# PIC32MZ1025W104132 device description
Architecture: MIPS; Family: PIC32MZW; Series: PIC32MZW
Registers are 32-bit, read-write, no defined reset value unless marked. A register's access mark holds for its fields unless they carry their own. Offsets are from the block's base; [hi:lo] are bit positions; lines under a group give offsets from that group; {n}, {i} and the like mark numbered series; 'fields as' and 'values as' point back to an identical list.

## INT
Instances: INT 0x1f810000 in periph_pb1b
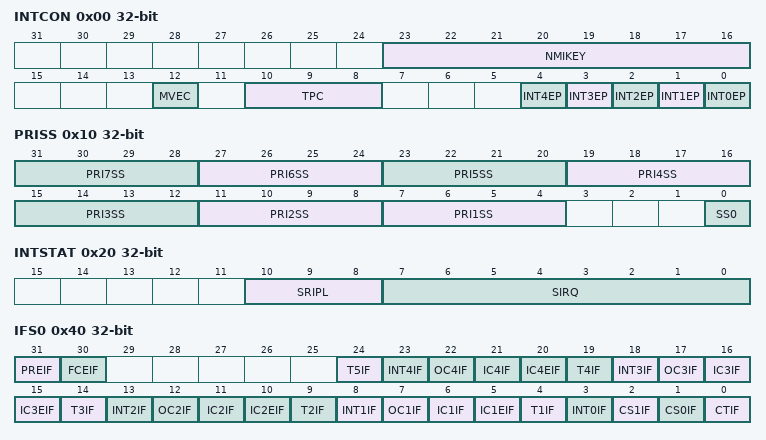
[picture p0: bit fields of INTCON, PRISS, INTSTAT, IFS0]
0x00 INTCON — Interrupt Control Register
  [23:16] NMIKEY
  [12] MVEC — Multi Vector Configuration bit
    1=Interrupt controller configured for multi vectored mode; 0=Interrupt controller configured for single vectored mode
  [10:8] TPC — Interrupt Proximity Timer Control bits
    {v}=Interrupts of group priority {v} or lower start the Interrupt Proximity timer (v=2..7); 1=Interrupts of group priority 1 start the Interrupt Proximity timer; 0=Disables Interrupt Proximity timer
  [n] INT{n}EP (n=0..4) — External Interrupt {n} Edge
    1=Rising edge; 0=Falling edge
0x10 PRISS — Priority Shadow Select Register
  [4n+3:4n] PRI{n}SS (n=2..7) — Interrupt with Priority Level {n} Shadow Set bits
    {v}=Interrupt with a priority level of {n} uses Shadow Set {v} (v=0..7)
  [7:4] PRI1SS — Interrupt with Priority Level 1 Shadow Set bits
    7=Interrupt with a priority level of 1 uses Shadow Set 7; {v}=Interrupt with a priority level of 1 uses Shadow Set {v} (v=0..5)
  [0] SS0 — Single Vector Shadow Register Set bit
    1=Single vector is presented with a shadow set; 0=Single vector is not presented with a shadow set
0x20 INTSTAT ro — Interrupt Status Register
  [10:8] SRIPL — Requested Priority Level bits for Single Vector Mode bits
    0=The priority level of the latest interrupt presented to the CPU is 0; 0=The priority level of the latest interrupt presented to the CPU is 1; 0=The priority level of the latest interrupt presented to the CPU is 2; 0=The priority level of the latest interrupt presented to the CPU is 3; 0=The priority level of the latest interrupt presented to the CPU is 4; 0=The priority level of the latest interrupt presented to the CPU is 5; 0=The priority level of the latest interrupt presented to the CPU is 6; 0=The priority level of the latest interrupt presented to the CPU is 7
  [7:0] SIRQ — Last Interrupt Request Serviced Status bits
    255=The last interrupt request number serviced by the CPU was 255; 254=The last interrupt request number serviced by the CPU was 254; 2=The last interrupt request number serviced by the CPU was 2; 1=The last interrupt request number serviced by the CPU was 1; 0=The last interrupt request number serviced by the CPU was 0
0x30 IPTMR — Interrupt Proximity Timer Register
  [31:0] IPTMR — Interrupt Proximity Timer Reload bits
    0=reload value of 0; 1=reload value of 1; 0xffffffff=reload value of 2^32-1
0x40 IFS0 — Interrupt Flag Status Register 0
  [all] fields
    1=Interrupt request has occurred; 0=No interrupt request has occurred
  [31] PREIF — Interrupt Flag Status bit 31
  [30] FCEIF — Interrupt Flag Status bit 30
  [5n-1] T{n}IF (n=1..5) — Interrupt Flag Status bit {5n-1}
  [5n+3] INT{n}IF (n=0..4) — Interrupt Flag Status bit {5n+3}
  [5n+2] OC{n}IF (n=1..4) — Interrupt Flag Status bit {5n+2}
  [5n+1] IC{n}IF (n=1..4) — Interrupt Flag Status bit {5n+1}
  [5n] IC{n}EIF (n=1..4) — Interrupt Flag Status bit {5n}
  [2] CS1IF — Interrupt Flag Status bit 2
  [1] CS0IF — Interrupt Flag Status bit 1
  [0] CTIF — Interrupt Flag Status bit 0
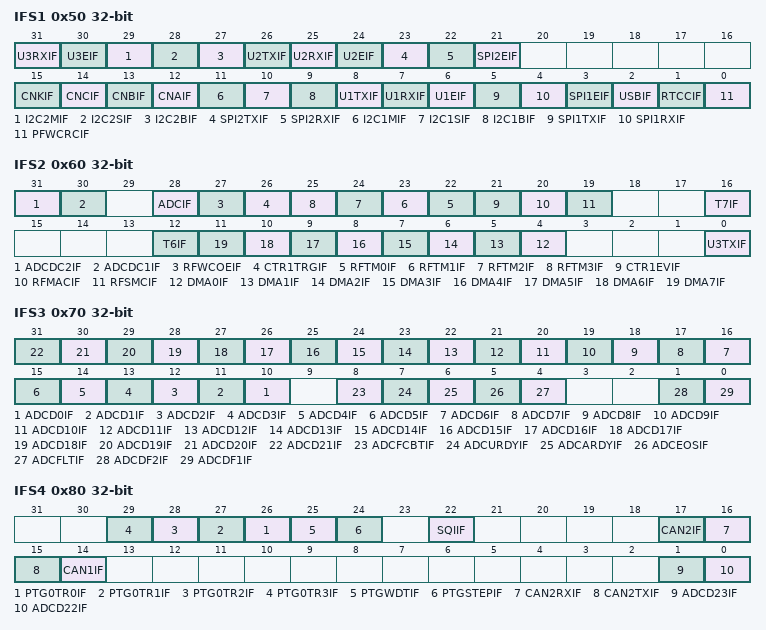
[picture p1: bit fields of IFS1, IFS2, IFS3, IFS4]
0x50 IFS1 — Interrupt Flag Status Register 1
  [all] fields
    values as the fields of IFS0
  [31] U3RXIF — Interrupt Flag Status bit 31
  [30] U3EIF — Interrupt Flag Status bit 30
  [29] I2C2MIF — Interrupt Flag Status bit 29
  [28] I2C2SIF — Interrupt Flag Status bit 28
  [27] I2C2BIF — Interrupt Flag Status bit 27
  [26] U2TXIF — Interrupt Flag Status bit 26
  [25] U2RXIF — Interrupt Flag Status bit 25
  [24] U2EIF — Interrupt Flag Status bit 24
  [23] SPI2TXIF — Interrupt Flag Status bit 23
  [22] SPI2RXIF — Interrupt Flag Status bit 22
  [21] SPI2EIF — Interrupt Flag Status bit 21
  [15] CNKIF — Interrupt Flag Status bit 15
  [14] CNCIF — Interrupt Flag Status bit 14
  [13] CNBIF — Interrupt Flag Status bit 13
  [12] CNAIF — Interrupt Flag Status bit 12
  [11] I2C1MIF — Interrupt Flag Status bit 11
  [10] I2C1SIF — Interrupt Flag Status bit 10
  [9] I2C1BIF — Interrupt Flag Status bit 9
  [8] U1TXIF — Interrupt Flag Status bit 8
  [7] U1RXIF — Interrupt Flag Status bit 7
  [6] U1EIF — Interrupt Flag Status bit 6
  [5] SPI1TXIF — Interrupt Flag Status bit 5
  [4] SPI1RXIF — Interrupt Flag Status bit 4
  [3] SPI1EIF — Interrupt Flag Status bit 3
  [2] USBIF — Interrupt Flag Status bit 2
  [1] RTCCIF — Interrupt Flag Status bit 1
  [0] PFWCRCIF — Interrupt Flag Status bit 0
0x60 IFS2 — Interrupt Flag Status Register 2
  [all] fields
    values as the fields of IFS0
  [31] ADCDC2IF — Interrupt Flag Status bit 31
  [30] ADCDC1IF — Interrupt Flag Status bit 30
  [28] ADCIF — Interrupt Flag Status bit 28
  [27] RFWCOEIF — Interrupt Flag Status bit 27
  [26] CTR1TRGIF — Interrupt Flag Status bit 26
  [n+22] RFTM{n}IF (n=0..3) — Interrupt Flag Status bit {n+22}
  [21] CTR1EVIF — Interrupt Flag Status bit 21
  [20] RFMACIF — Interrupt Flag Status bit 20
  [19] RFSMCIF — Interrupt Flag Status bit 19
  [16] T7IF — Interrupt Flag Status bit 16
  [12] T6IF — Interrupt Flag Status bit 12
  [n+4] DMA{n}IF (n=0..7) — Interrupt Flag Status bit {n+4}
  [0] U3TXIF — Interrupt Flag Status bit 0
0x70 IFS3 — Interrupt Flag Status Register 3
  [all] fields
    values as the fields of IFS0
  [n+10] ADCD{n}IF (n=0..21) — Interrupt Flag Status bit {n+10}
  [8] ADCFCBTIF — Interrupt Flag Status bit 8
  [7] ADCURDYIF — Interrupt Flag Status bit 7
  [6] ADCARDYIF — Interrupt Flag Status bit 6
  [5] ADCEOSIF — Interrupt Flag Status bit 5
  [4] ADCFLTIF — Interrupt Flag Status bit 4
  [1] ADCDF2IF — Interrupt Flag Status bit 1
  [0] ADCDF1IF — Interrupt Flag Status bit 0
0x80 IFS4 — Interrupt Flag Status Register 4
  [all] fields
    values as the fields of IFS0
  [n+26] PTG0TR{n}IF (n=0..3) — Interrupt Flag Status bit {n+26}
  [25] PTGWDTIF — Interrupt Flag Status bit 25
  [24] PTGSTEPIF — Interrupt Flag Status bit 24
  [22] SQIIF — Interrupt Flag Status bit 22
  [17] CAN2IF — Interrupt Flag Status bit 17
  [16] CAN2RXIF — Interrupt Flag Status bit 16
  [15] CAN2TXIF — Interrupt Flag Status bit 15
  [14] CAN1IF — Interrupt Flag Status bit 14
  [1] ADCD23IF — Interrupt Flag Status bit 1
  [0] ADCD22IF — Interrupt Flag Status bit 0
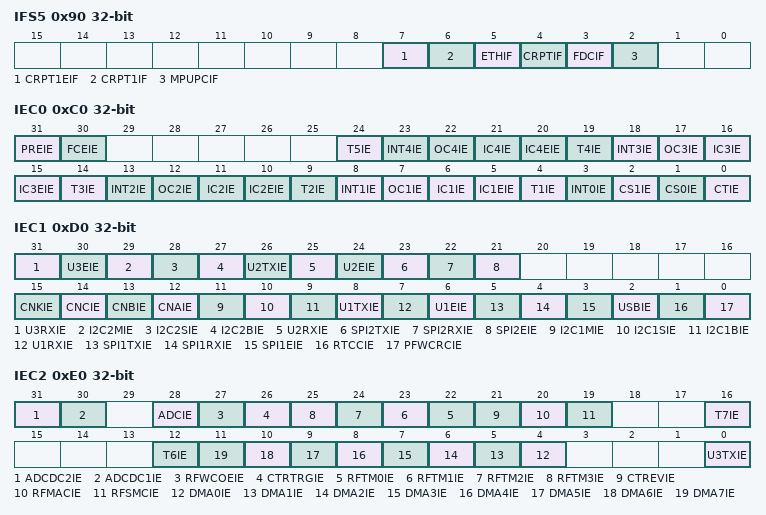
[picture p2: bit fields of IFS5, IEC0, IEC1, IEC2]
0x90 IFS5 — Interrupt Flag Status Register 5
  [all] fields
    values as the fields of IFS0
  [7] CRPT1EIF — Interrupt Flag Status bit 7
  [6] CRPT1IF — Interrupt Flag Status bit 6
  [5] ETHIF — Interrupt Flag Status bit 5
  [4] CRPTIF — Interrupt Flag Status bit 4
  [3] FDCIF — Interrupt Flag Status bit 3
  [2] MPUPCIF — Interrupt Flag Status bit 2
0xC0 IEC0 — Interrupt Enable Control Register 0
  [all] fields
    1=Interrupt is enabled; 0=Interrupt is disabled
  [31] PREIE — Interrupt Enable bit 31
  [30] FCEIE — Interrupt Enable bit 30
  [5n-1] T{n}IE (n=1..5) — Interrupt Enable bit {5n-1}
  [5n+3] INT{n}IE (n=0..4) — Interrupt Enable bit {5n+3}
  [5n+2] OC{n}IE (n=1..4) — Interrupt Enable bit {5n+2}
  [5n+1] IC{n}IE (n=1..4) — Interrupt Enable bit {5n+1}
  [5n] IC{n}EIE (n=1..4) — Interrupt Enable bit {5n}
  [2] CS1IE — Interrupt Enable bit 2
  [1] CS0IE — Interrupt Enable bit 1
  [0] CTIE — Interrupt Enable bit 0
0xD0 IEC1 — Interrupt Enable Control Register 1
  [all] fields
    1=Interrupt is enabled; 0=Interrupt is disabled
  [31] U3RXIE — Interrupt Enable bit 31
  [30] U3EIE — Interrupt Enable bit 30
  [29] I2C2MIE — Interrupt Enable bit 29
  [28] I2C2SIE — Interrupt Enable bit 28
  [27] I2C2BIE — Interrupt Enable bit 27
  [26] U2TXIE — Interrupt Enable bit 26
  [25] U2RXIE — Interrupt Enable bit 25
  [24] U2EIE — Interrupt Enable bit 24
  [23] SPI2TXIE — Interrupt Enable bit 23
  [22] SPI2RXIE — Interrupt Enable bit 22
  [21] SPI2EIE — Interrupt Enable bit 21
  [15] CNKIE — Interrupt Enable bit 15
  [14] CNCIE — Interrupt Enable bit 14
  [13] CNBIE — Interrupt Enable bit 13
  [12] CNAIE — Interrupt Enable bit 12
  [11] I2C1MIE — Interrupt Enable bit 11
  [10] I2C1SIE — Interrupt Enable bit 10
  [9] I2C1BIE — Interrupt Enable bit 9
  [8] U1TXIE — Interrupt Enable bit 8
  [7] U1RXIE — Interrupt Enable bit 7
  [6] U1EIE — Interrupt Enable bit 6
  [5] SPI1TXIE — Interrupt Enable bit 5
  [4] SPI1RXIE — Interrupt Enable bit 4
  [3] SPI1EIE — Interrupt Enable bit 3
  [2] USBIE — Interrupt Enable bit 2
  [1] RTCCIE — Interrupt Enable bit 1
  [0] PFWCRCIE — Interrupt Enable bit 0
0xE0 IEC2 — Interrupt Enable Control Register 2
  [all] fields
    1=Interrupt is enabled; 0=Interrupt is disabled
  [31] ADCDC2IE — Interrupt Enable bit 31
  [30] ADCDC1IE — Interrupt Enable bit 30
  [28] ADCIE — Interrupt Enable bit 28
  [27] RFWCOEIE — Interrupt Enable bit 27
  [26] CTRTRGIE — Interrupt Enable bit 26
  [n+22] RFTM{n}IE (n=0..3) — Interrupt Enable bit {n+22}
  [21] CTREVIE — Interrupt Enable bit 21
  [20] RFMACIE — Interrupt Enable bit 20
  [19] RFSMCIE — Interrupt Enable bit 19
  [16] T7IE — Interrupt Enable bit 16
  [12] T6IE — Interrupt Enable bit 12
  [n+4] DMA{n}IE (n=0..7) — Interrupt Enable bit {n+4}
  [0] U3TXIE — Interrupt Enable bit 0
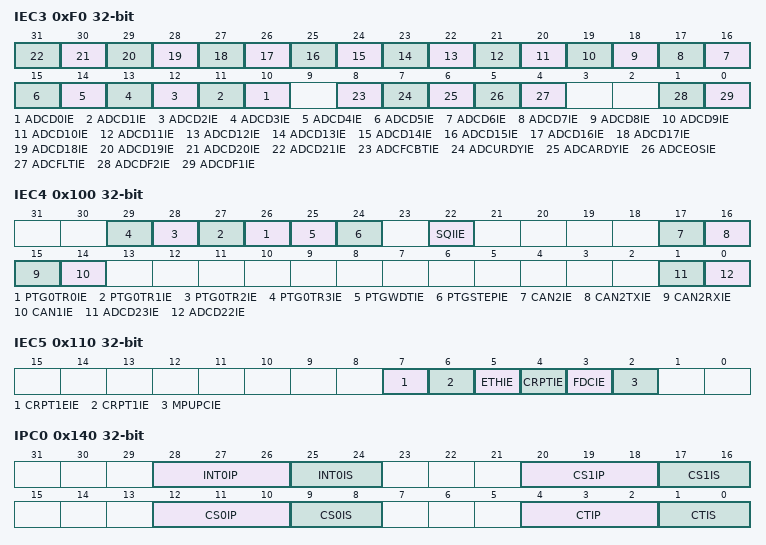
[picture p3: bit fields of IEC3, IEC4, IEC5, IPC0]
0xF0 IEC3 — Interrupt Enable Control Register 3
  [all] fields
    1=Interrupt is enabled; 0=Interrupt is disabled
  [n+10] ADCD{n}IE (n=0..21) — Interrupt Enable bit {n+10}
  [8] ADCFCBTIE — Interrupt Enable bit 8
  [7] ADCURDYIE — Interrupt Enable bit 7
  [6] ADCARDYIE — Interrupt Enable bit 6
  [5] ADCEOSIE — Interrupt Enable bit 5
  [4] ADCFLTIE — Interrupt Enable bit 4
  [1] ADCDF2IE — Interrupt Enable bit 1
  [0] ADCDF1IE — Interrupt Enable bit 0
0x100 IEC4 — Interrupt Enable Control Register 4
  [all] fields
    1=Interrupt is enabled; 0=Interrupt is disabled
  [n+26] PTG0TR{n}IE (n=0..3) — Interrupt Enable bit {n+26}
  [25] PTGWDTIE — Interrupt Enable bit 25
  [24] PTGSTEPIE — Interrupt Enable bit 24
  [22] SQIIE — Interrupt Enable bit 22
  [17] CAN2IE — Interrupt Enable bit 17
  [16] CAN2TXIE — Interrupt Enable bit 16
  [15] CAN2RXIE — Interrupt Enable bit 15
  [14] CAN1IE — Interrupt Enable bit 14
  [1] ADCD23IE — Interrupt Enable bit 1
  [0] ADCD22IE — Interrupt Enable bit 0
0x110 IEC5 — Interrupt Enable Control Register 5
  [all] fields
    1=Interrupt is enabled; 0=Interrupt is disabled
  [7] CRPT1EIE — Interrupt Enable bit 7
  [6] CRPT1IE — Interrupt Enable bit 6
  [5] ETHIE — Interrupt Enable bit 5
  [4] CRPTIE — Interrupt Enable bit 4
  [3] FDCIE — Interrupt Enable bit 3
  [2] MPUPCIE — Interrupt Enable bit 2
0x140 IPC0 — Interrupt Priority Control Register 0
  [28:26] INT0IP — Interrupt priority
    {v}=Interrupt priority is {v} (v=1..7); 0=Interrupt is disabled
  [25:24] INT0IS — Interrupt subpriority
    {v}=Interrupt subpriority is {v} (v=0..3)
  [20:18] CS1IP — Interrupt priority
    values as INT0IP
  [17:16] CS1IS — Interrupt subpriority
    {v}=Interrupt subpriority is {v} (v=0..3)
  [12:10] CS0IP — Interrupt priority
    values as INT0IP
  [9:8] CS0IS — Interrupt subpriority
    {v}=Interrupt subpriority is {v} (v=0..3)
  [4:2] CTIP — Interrupt priority
    values as INT0IP
  [1:0] CTIS — Interrupt subpriority
    {v}=Interrupt subpriority is {v} (v=0..3)
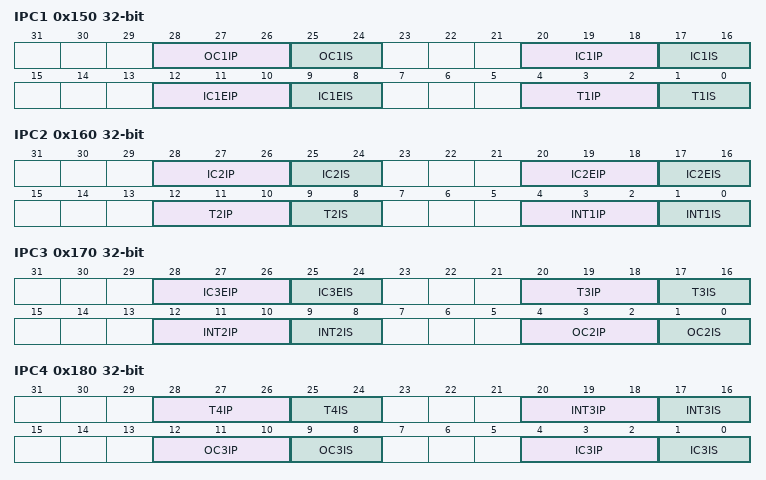
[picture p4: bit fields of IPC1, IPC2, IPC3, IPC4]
0x150 IPC1 — Interrupt Priority Control Register 1
  [28:26] OC1IP — Interrupt priority
    values as IPC0.INT0IP
  [25:24] OC1IS — Interrupt subpriority
    {v}=Interrupt subpriority is {v} (v=0..3)
  [20:18] IC1IP — Interrupt priority
    values as IPC0.INT0IP
  [17:16] IC1IS — Interrupt subpriority
    {v}=Interrupt subpriority is {v} (v=0..3)
  [12:10] IC1EIP — Interrupt priority
    values as IPC0.INT0IP
  [9:8] IC1EIS — Interrupt subpriority
    {v}=Interrupt subpriority is {v} (v=0..3)
  [4:2] T1IP — Interrupt priority
    values as IPC0.INT0IP
  [1:0] T1IS — Interrupt subpriority
    {v}=Interrupt subpriority is {v} (v=0..3)
0x160 IPC2 — Interrupt Priority Control Register 2
  [28:26] IC2IP — Interrupt priority
    values as IPC0.INT0IP
  [25:24] IC2IS — Interrupt subpriority
    {v}=Interrupt subpriority is {v} (v=0..3)
  [20:18] IC2EIP — Interrupt priority
    values as IPC0.INT0IP
  [17:16] IC2EIS — Interrupt subpriority
    {v}=Interrupt subpriority is {v} (v=0..3)
  [12:10] T2IP — Interrupt priority
    values as IPC0.INT0IP
  [9:8] T2IS — Interrupt subpriority
    {v}=Interrupt subpriority is {v} (v=0..3)
  [4:2] INT1IP — Interrupt priority
    values as IPC0.INT0IP
  [1:0] INT1IS — Interrupt subpriority
    {v}=Interrupt subpriority is {v} (v=0..3)
0x170 IPC3 — Interrupt Priority Control Register 3
  [28:26] IC3EIP — Interrupt priority
    values as IPC0.INT0IP
  [25:24] IC3EIS — Interrupt subpriority
    {v}=Interrupt subpriority is {v} (v=0..3)
  [20:18] T3IP — Interrupt priority
    values as IPC0.INT0IP
  [17:16] T3IS — Interrupt subpriority
    {v}=Interrupt subpriority is {v} (v=0..3)
  [12:10] INT2IP — Interrupt priority
    values as IPC0.INT0IP
  [9:8] INT2IS — Interrupt subpriority
    {v}=Interrupt subpriority is {v} (v=0..3)
  [4:2] OC2IP — Interrupt priority
    values as IPC0.INT0IP
  [1:0] OC2IS — Interrupt subpriority
    {v}=Interrupt subpriority is {v} (v=0..3)
0x180 IPC4 — Interrupt Priority Control Register 4
  [28:26] T4IP — Interrupt priority
    values as IPC0.INT0IP
  [25:24] T4IS — Interrupt subpriority
    {v}=Interrupt subpriority is {v} (v=0..3)
  [20:18] INT3IP — Interrupt priority
    values as IPC0.INT0IP
  [17:16] INT3IS — Interrupt subpriority
    {v}=Interrupt subpriority is {v} (v=0..3)
  [12:10] OC3IP — Interrupt priority
    values as IPC0.INT0IP
  [9:8] OC3IS — Interrupt subpriority
    {v}=Interrupt subpriority is {v} (v=0..3)
  [4:2] IC3IP — Interrupt priority
    values as IPC0.INT0IP
  [1:0] IC3IS — Interrupt subpriority
    {v}=Interrupt subpriority is {v} (v=0..3)
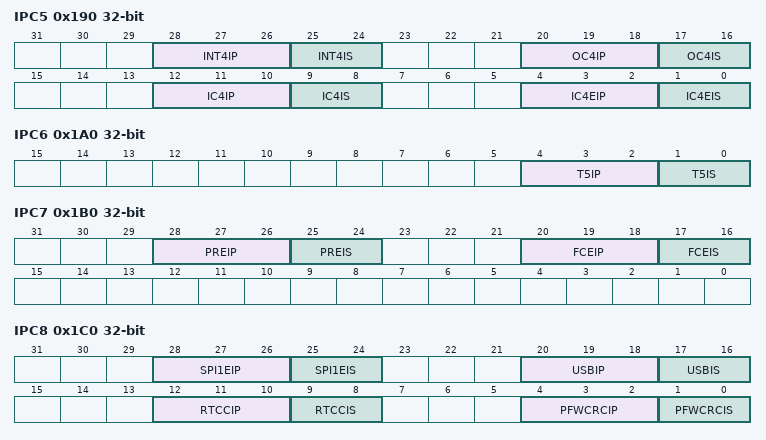
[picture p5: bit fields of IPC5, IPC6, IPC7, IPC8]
0x190 IPC5 — Interrupt Priority Control Register 5
  [28:26] INT4IP — Interrupt priority
    values as IPC0.INT0IP
  [25:24] INT4IS — Interrupt subpriority
    {v}=Interrupt subpriority is {v} (v=0..3)
  [20:18] OC4IP — Interrupt priority
    values as IPC0.INT0IP
  [17:16] OC4IS — Interrupt subpriority
    {v}=Interrupt subpriority is {v} (v=0..3)
  [12:10] IC4IP — Interrupt priority
    values as IPC0.INT0IP
  [9:8] IC4IS — Interrupt subpriority
    {v}=Interrupt subpriority is {v} (v=0..3)
  [4:2] IC4EIP — Interrupt priority
    values as IPC0.INT0IP
  [1:0] IC4EIS — Interrupt subpriority
    {v}=Interrupt subpriority is {v} (v=0..3)
0x1A0 IPC6 — Interrupt Priority Control Register 6
  [4:2] T5IP — Interrupt priority
    values as IPC0.INT0IP
  [1:0] T5IS — Interrupt subpriority
    {v}=Interrupt subpriority is {v} (v=0..3)
0x1B0 IPC7 — Interrupt Priority Control Register 7
  [28:26] PREIP — Interrupt priority
    values as IPC0.INT0IP
  [25:24] PREIS — Interrupt subpriority
    {v}=Interrupt subpriority is {v} (v=0..3)
  [20:18] FCEIP — Interrupt priority
    values as IPC0.INT0IP
  [17:16] FCEIS — Interrupt subpriority
    {v}=Interrupt subpriority is {v} (v=0..3)
0x1C0 IPC8 — Interrupt Priority Control Register 8
  [28:26] SPI1EIP — Interrupt priority
    values as IPC0.INT0IP
  [25:24] SPI1EIS — Interrupt subpriority
    {v}=Interrupt subpriority is {v} (v=0..3)
  [20:18] USBIP — Interrupt priority
    values as IPC0.INT0IP
  [17:16] USBIS — Interrupt subpriority
    {v}=Interrupt subpriority is {v} (v=0..3)
  [12:10] RTCCIP — Interrupt priority
    values as IPC0.INT0IP
  [9:8] RTCCIS — Interrupt subpriority
    {v}=Interrupt subpriority is {v} (v=0..3)
  [4:2] PFWCRCIP — Interrupt priority
    values as IPC0.INT0IP
  [1:0] PFWCRCIS — Interrupt subpriority
    {v}=Interrupt subpriority is {v} (v=0..3)
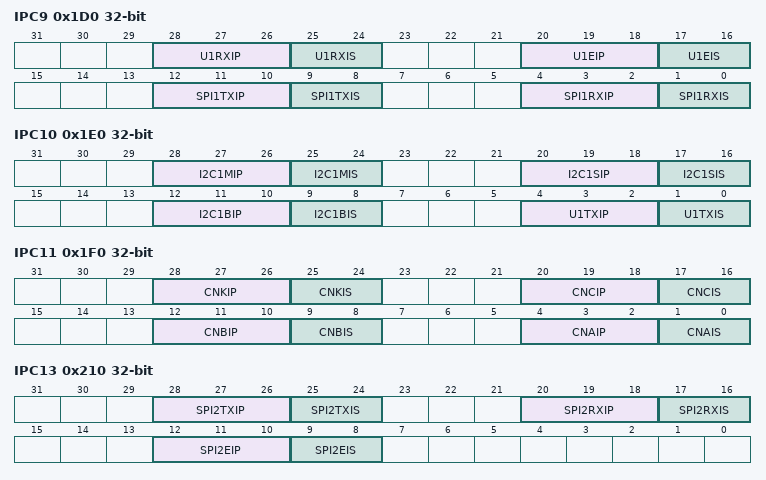
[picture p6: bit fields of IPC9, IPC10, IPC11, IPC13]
0x1D0 IPC9 — Interrupt Priority Control Register 9
  [28:26] U1RXIP — Interrupt priority
    values as IPC0.INT0IP
  [25:24] U1RXIS — Interrupt subpriority
    {v}=Interrupt subpriority is {v} (v=0..3)
  [20:18] U1EIP — Interrupt priority
    values as IPC0.INT0IP
  [17:16] U1EIS — Interrupt subpriority
    {v}=Interrupt subpriority is {v} (v=0..3)
  [12:10] SPI1TXIP — Interrupt priority
    values as IPC0.INT0IP
  [9:8] SPI1TXIS — Interrupt subpriority
    {v}=Interrupt subpriority is {v} (v=0..3)
  [4:2] SPI1RXIP — Interrupt priority
    values as IPC0.INT0IP
  [1:0] SPI1RXIS — Interrupt subpriority
    {v}=Interrupt subpriority is {v} (v=0..3)
0x1E0 IPC10 — Interrupt Priority Control Register 10
  [28:26] I2C1MIP — Interrupt priority
    values as IPC0.INT0IP
  [25:24] I2C1MIS — Interrupt subpriority
    {v}=Interrupt subpriority is {v} (v=0..3)
  [20:18] I2C1SIP — Interrupt priority
    values as IPC0.INT0IP
  [17:16] I2C1SIS — Interrupt subpriority
    {v}=Interrupt subpriority is {v} (v=0..3)
  [12:10] I2C1BIP — Interrupt priority
    values as IPC0.INT0IP
  [9:8] I2C1BIS — Interrupt subpriority
    {v}=Interrupt subpriority is {v} (v=0..3)
  [4:2] U1TXIP — Interrupt priority
    values as IPC0.INT0IP
  [1:0] U1TXIS — Interrupt subpriority
    {v}=Interrupt subpriority is {v} (v=0..3)
0x1F0 IPC11 — Interrupt Priority Control Register 11
  [28:26] CNKIP — Interrupt priority
    values as IPC0.INT0IP
  [25:24] CNKIS — Interrupt subpriority
    {v}=Interrupt subpriority is {v} (v=0..3)
  [20:18] CNCIP — Interrupt priority
    values as IPC0.INT0IP
  [17:16] CNCIS — Interrupt subpriority
    {v}=Interrupt subpriority is {v} (v=0..3)
  [12:10] CNBIP — Interrupt priority
    values as IPC0.INT0IP
  [9:8] CNBIS — Interrupt subpriority
    {v}=Interrupt subpriority is {v} (v=0..3)
  [4:2] CNAIP — Interrupt priority
    values as IPC0.INT0IP
  [1:0] CNAIS — Interrupt subpriority
    {v}=Interrupt subpriority is {v} (v=0..3)
0x210 IPC13 — Interrupt Priority Control Register 13
  [28:26] SPI2TXIP — Interrupt priority
    values as IPC0.INT0IP
  [25:24] SPI2TXIS — Interrupt subpriority
    {v}=Interrupt subpriority is {v} (v=0..3)
  [20:18] SPI2RXIP — Interrupt priority
    values as IPC0.INT0IP
  [17:16] SPI2RXIS — Interrupt subpriority
    {v}=Interrupt subpriority is {v} (v=0..3)
  [12:10] SPI2EIP — Interrupt priority
    values as IPC0.INT0IP
  [9:8] SPI2EIS — Interrupt subpriority
    {v}=Interrupt subpriority is {v} (v=0..3)
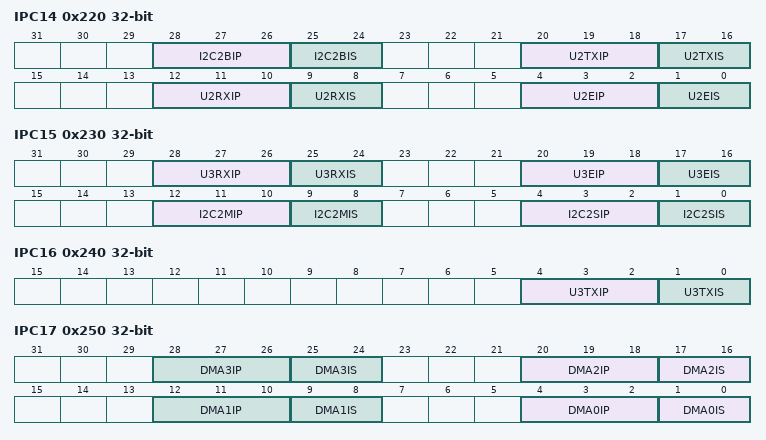
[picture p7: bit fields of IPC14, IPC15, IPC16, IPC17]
0x220 IPC14 — Interrupt Priority Control Register 14
  [28:26] I2C2BIP — Interrupt priority
    values as IPC0.INT0IP
  [25:24] I2C2BIS — Interrupt subpriority
    {v}=Interrupt subpriority is {v} (v=0..3)
  [20:18] U2TXIP — Interrupt priority
    values as IPC0.INT0IP
  [17:16] U2TXIS — Interrupt subpriority
    {v}=Interrupt subpriority is {v} (v=0..3)
  [12:10] U2RXIP — Interrupt priority
    values as IPC0.INT0IP
  [9:8] U2RXIS — Interrupt subpriority
    {v}=Interrupt subpriority is {v} (v=0..3)
  [4:2] U2EIP — Interrupt priority
    values as IPC0.INT0IP
  [1:0] U2EIS — Interrupt subpriority
    {v}=Interrupt subpriority is {v} (v=0..3)
0x230 IPC15 — Interrupt Priority Control Register 15
  [28:26] U3RXIP — Interrupt priority
    values as IPC0.INT0IP
  [25:24] U3RXIS — Interrupt subpriority
    {v}=Interrupt subpriority is {v} (v=0..3)
  [20:18] U3EIP — Interrupt priority
    values as IPC0.INT0IP
  [17:16] U3EIS — Interrupt subpriority
    {v}=Interrupt subpriority is {v} (v=0..3)
  [12:10] I2C2MIP — Interrupt priority
    values as IPC0.INT0IP
  [9:8] I2C2MIS — Interrupt subpriority
    {v}=Interrupt subpriority is {v} (v=0..3)
  [4:2] I2C2SIP — Interrupt priority
    values as IPC0.INT0IP
  [1:0] I2C2SIS — Interrupt subpriority
    {v}=Interrupt subpriority is {v} (v=0..3)
0x240 IPC16 — Interrupt Priority Control Register 16
  [4:2] U3TXIP — Interrupt priority
    values as IPC0.INT0IP
  [1:0] U3TXIS — Interrupt subpriority
    {v}=Interrupt subpriority is {v} (v=0..3)
0x250 IPC17 — Interrupt Priority Control Register 17
  [8n+4:8n+2] DMA{n}IP (n=0..3) — Interrupt priority
    values as IPC0.INT0IP
  [8n+1:8n] DMA{n}IS (n=0..3) — Interrupt subpriority
    {v}=Interrupt subpriority is {v} (v=0..3)
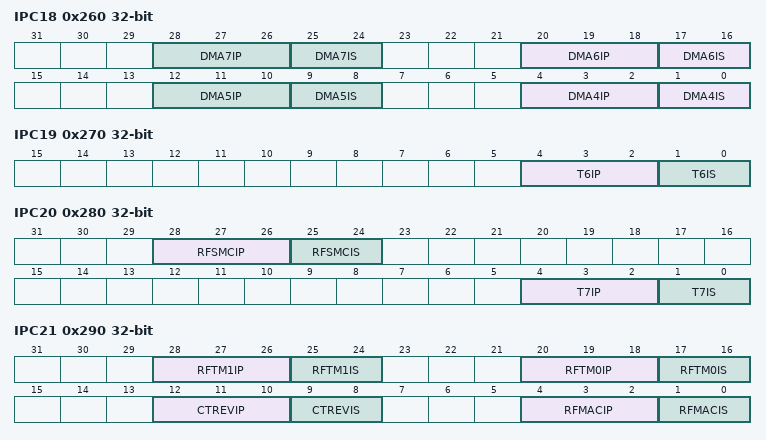
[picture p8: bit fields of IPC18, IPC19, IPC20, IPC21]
0x260 IPC18 — Interrupt Priority Control Register 18
  [8n-28:8n-30] DMA{n}IP (n=4..7) — Interrupt priority
    values as IPC0.INT0IP
  [8n-31:8n-32] DMA{n}IS (n=4..7) — Interrupt subpriority
    {v}=Interrupt subpriority is {v} (v=0..3)
0x270 IPC19 — Interrupt Priority Control Register 19
  [4:2] T6IP — Interrupt priority
    values as IPC0.INT0IP
  [1:0] T6IS — Interrupt subpriority
    {v}=Interrupt subpriority is {v} (v=0..3)
0x280 IPC20 — Interrupt Priority Control Register 20
  [28:26] RFSMCIP — Interrupt priority
    values as IPC0.INT0IP
  [25:24] RFSMCIS — Interrupt subpriority
    {v}=Interrupt subpriority is {v} (v=0..3)
  [4:2] T7IP — Interrupt priority
    values as IPC0.INT0IP
  [1:0] T7IS — Interrupt subpriority
    {v}=Interrupt subpriority is {v} (v=0..3)
0x290 IPC21 — Interrupt Priority Control Register 21
  [28:26] RFTM1IP — Interrupt priority
    values as IPC0.INT0IP
  [25:24] RFTM1IS — Interrupt subpriority
    {v}=Interrupt subpriority is {v} (v=0..3)
  [20:18] RFTM0IP — Interrupt priority
    values as IPC0.INT0IP
  [17:16] RFTM0IS — Interrupt subpriority
    {v}=Interrupt subpriority is {v} (v=0..3)
  [12:10] CTREVIP — Interrupt priority
    values as IPC0.INT0IP
  [9:8] CTREVIS — Interrupt subpriority
    {v}=Interrupt subpriority is {v} (v=0..3)
  [4:2] RFMACIP — Interrupt priority
    values as IPC0.INT0IP
  [1:0] RFMACIS — Interrupt subpriority
    {v}=Interrupt subpriority is {v} (v=0..3)
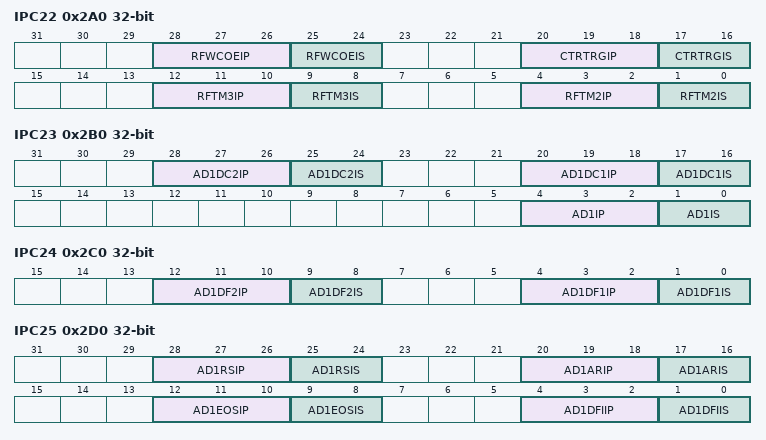
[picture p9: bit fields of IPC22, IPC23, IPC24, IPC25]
0x2A0 IPC22 — Interrupt Priority Control Register 22
  [28:26] RFWCOEIP — Interrupt priority
    values as IPC0.INT0IP
  [25:24] RFWCOEIS — Interrupt subpriority
    {v}=Interrupt subpriority is {v} (v=0..3)
  [20:18] CTRTRGIP — Interrupt priority
    values as IPC0.INT0IP
  [17:16] CTRTRGIS — Interrupt subpriority
    {v}=Interrupt subpriority is {v} (v=0..3)
  [12:10] RFTM3IP — Interrupt priority
    values as IPC0.INT0IP
  [9:8] RFTM3IS — Interrupt subpriority
    {v}=Interrupt subpriority is {v} (v=0..3)
  [4:2] RFTM2IP — Interrupt priority
    values as IPC0.INT0IP
  [1:0] RFTM2IS — Interrupt subpriority
    {v}=Interrupt subpriority is {v} (v=0..3)
0x2B0 IPC23 — Interrupt Priority Control Register 23
  [28:26] AD1DC2IP — Interrupt priority
    values as IPC0.INT0IP
  [25:24] AD1DC2IS — Interrupt subpriority
    {v}=Interrupt subpriority is {v} (v=0..3)
  [20:18] AD1DC1IP — Interrupt priority
    values as IPC0.INT0IP
  [17:16] AD1DC1IS — Interrupt subpriority
    {v}=Interrupt subpriority is {v} (v=0..3)
  [4:2] AD1IP — Interrupt priority
    values as IPC0.INT0IP
  [1:0] AD1IS — Interrupt subpriority
    {v}=Interrupt subpriority is {v} (v=0..3)
0x2C0 IPC24 — Interrupt Priority Control Register 24
  [12:10] AD1DF2IP — Interrupt priority
    values as IPC0.INT0IP
  [9:8] AD1DF2IS — Interrupt subpriority
    {v}=Interrupt subpriority is {v} (v=0..3)
  [4:2] AD1DF1IP — Interrupt priority
    values as IPC0.INT0IP
  [1:0] AD1DF1IS — Interrupt subpriority
    {v}=Interrupt subpriority is {v} (v=0..3)
0x2D0 IPC25 — Interrupt Priority Control Register 25
  [28:26] AD1RSIP — Interrupt priority
    values as IPC0.INT0IP
  [25:24] AD1RSIS — Interrupt subpriority
    {v}=Interrupt subpriority is {v} (v=0..3)
  [20:18] AD1ARIP — Interrupt priority
    values as IPC0.INT0IP
  [17:16] AD1ARIS — Interrupt subpriority
    {v}=Interrupt subpriority is {v} (v=0..3)
  [12:10] AD1EOSIP — Interrupt priority
    values as IPC0.INT0IP
  [9:8] AD1EOSIS — Interrupt subpriority
    {v}=Interrupt subpriority is {v} (v=0..3)
  [4:2] AD1DFIIP — Interrupt priority
    values as IPC0.INT0IP
  [1:0] AD1DFIIS — Interrupt subpriority
    {v}=Interrupt subpriority is {v} (v=0..3)
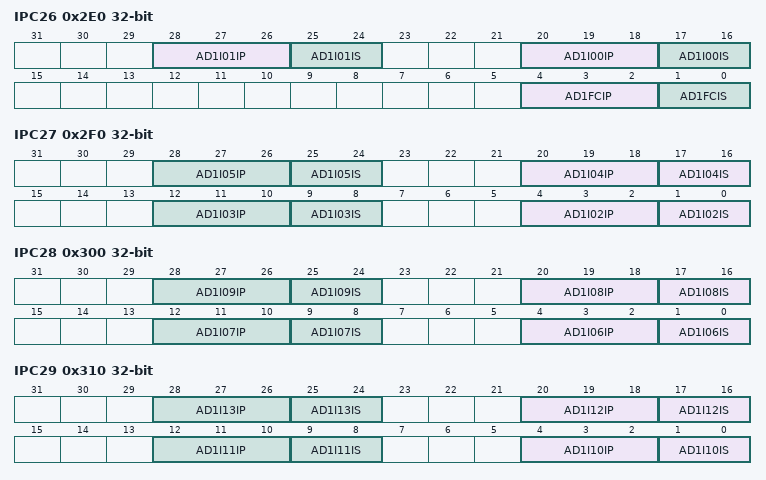
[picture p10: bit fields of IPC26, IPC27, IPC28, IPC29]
0x2E0 IPC26 — Interrupt Priority Control Register 26
  [28:26] AD1I01IP — Interrupt priority
    values as IPC0.INT0IP
  [25:24] AD1I01IS — Interrupt subpriority
    {v}=Interrupt subpriority is {v} (v=0..3)
  [20:18] AD1I00IP — Interrupt priority
    values as IPC0.INT0IP
  [17:16] AD1I00IS — Interrupt subpriority
    {v}=Interrupt subpriority is {v} (v=0..3)
  [4:2] AD1FCIP — Interrupt priority
    values as IPC0.INT0IP
  [1:0] AD1FCIS — Interrupt subpriority
    {v}=Interrupt subpriority is {v} (v=0..3)
0x2F0 IPC27 — Interrupt Priority Control Register 27
  [8n-12:8n-14] AD1I{n:02}IP (n=2..5) — Interrupt priority
    values as IPC0.INT0IP
  [8n-15:8n-16] AD1I{n:02}IS (n=2..5) — Interrupt subpriority
    {v}=Interrupt subpriority is {v} (v=0..3)
0x300 IPC28 — Interrupt Priority Control Register 28
  [8n-44:8n-46] AD1I{n:02}IP (n=6..9) — Interrupt priority
    values as IPC0.INT0IP
  [8n-47:8n-48] AD1I{n:02}IS (n=6..9) — Interrupt subpriority
    {v}=Interrupt subpriority is {v} (v=0..3)
0x310 IPC29 — Interrupt Priority Control Register 29
  [8n-76:8n-78] AD1I{n}IP (n=10..13) — Interrupt priority
    values as IPC0.INT0IP
  [8n-79:8n-80] AD1I{n}IS (n=10..13) — Interrupt subpriority
    {v}=Interrupt subpriority is {v} (v=0..3)
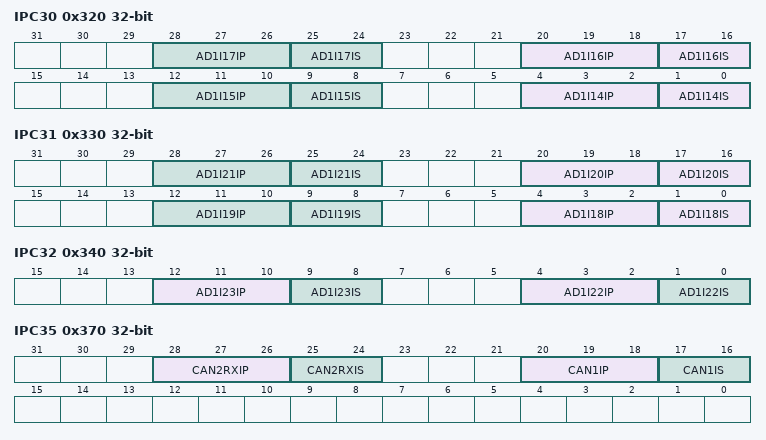
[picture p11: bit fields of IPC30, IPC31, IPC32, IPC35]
0x320 IPC30 — Interrupt Priority Control Register 30
  [8n-108:8n-110] AD1I{n}IP (n=14..17) — Interrupt priority
    values as IPC0.INT0IP
  [8n-111:8n-112] AD1I{n}IS (n=14..17) — Interrupt subpriority
    {v}=Interrupt subpriority is {v} (v=0..3)
0x330 IPC31 — Interrupt Priority Control Register 31
  [8n-140:8n-142] AD1I{n}IP (n=18..21) — Interrupt priority
    values as IPC0.INT0IP
  [8n-143:8n-144] AD1I{n}IS (n=18..21) — Interrupt subpriority
    {v}=Interrupt subpriority is {v} (v=0..3)
0x340 IPC32 — Interrupt Priority Control Register 32
  [12:10] AD1I23IP — Interrupt priority
    values as IPC0.INT0IP
  [9:8] AD1I23IS — Interrupt subpriority
    {v}=Interrupt subpriority is {v} (v=0..3)
  [4:2] AD1I22IP — Interrupt priority
    values as IPC0.INT0IP
  [1:0] AD1I22IS — Interrupt subpriority
    {v}=Interrupt subpriority is {v} (v=0..3)
0x370 IPC35 — Interrupt Priority Control Register 35
  [28:26] CAN2RXIP — Interrupt priority
    values as IPC0.INT0IP
  [25:24] CAN2RXIS — Interrupt subpriority
    {v}=Interrupt subpriority is {v} (v=0..3)
  [20:18] CAN1IP — Interrupt priority
    values as IPC0.INT0IP
  [17:16] CAN1IS — Interrupt subpriority
    {v}=Interrupt subpriority is {v} (v=0..3)
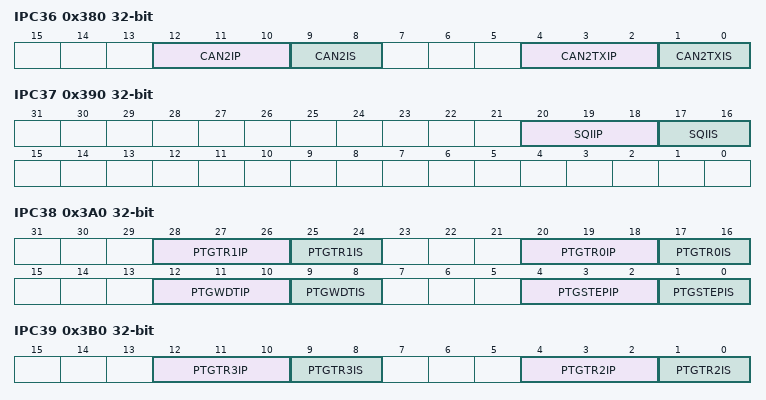
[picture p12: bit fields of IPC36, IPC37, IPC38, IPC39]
0x380 IPC36 — Interrupt Priority Control Register 36
  [12:10] CAN2IP — Interrupt priority
    values as IPC0.INT0IP
  [9:8] CAN2IS — Interrupt subpriority
    {v}=Interrupt subpriority is {v} (v=0..3)
  [4:2] CAN2TXIP — Interrupt priority
    values as IPC0.INT0IP
  [1:0] CAN2TXIS — Interrupt subpriority
    {v}=Interrupt subpriority is {v} (v=0..3)
0x390 IPC37 — Interrupt Priority Control Register 37
  [20:18] SQIIP — Interrupt priority
    values as IPC0.INT0IP
  [17:16] SQIIS — Interrupt subpriority
    {v}=Interrupt subpriority is {v} (v=0..3)
0x3A0 IPC38 — Interrupt Priority Control Register 38
  [28:26] PTGTR1IP — Interrupt priority
    values as IPC0.INT0IP
  [25:24] PTGTR1IS — Interrupt subpriority
    {v}=Interrupt subpriority is {v} (v=0..3)
  [20:18] PTGTR0IP — Interrupt priority
    values as IPC0.INT0IP
  [17:16] PTGTR0IS — Interrupt subpriority
    {v}=Interrupt subpriority is {v} (v=0..3)
  [12:10] PTGWDTIP — Interrupt priority
    values as IPC0.INT0IP
  [9:8] PTGWDTIS — Interrupt subpriority
    {v}=Interrupt subpriority is {v} (v=0..3)
  [4:2] PTGSTEPIP — Interrupt priority
    values as IPC0.INT0IP
  [1:0] PTGSTEPIS — Interrupt subpriority
    {v}=Interrupt subpriority is {v} (v=0..3)
0x3B0 IPC39 — Interrupt Priority Control Register 39
  [12:10] PTGTR3IP — Interrupt priority
    values as IPC0.INT0IP
  [9:8] PTGTR3IS — Interrupt subpriority
    {v}=Interrupt subpriority is {v} (v=0..3)
  [4:2] PTGTR2IP — Interrupt priority
    values as IPC0.INT0IP
  [1:0] PTGTR2IS — Interrupt subpriority
    {v}=Interrupt subpriority is {v} (v=0..3)
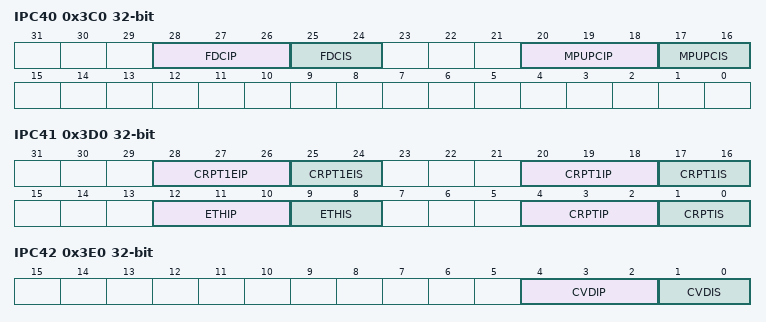
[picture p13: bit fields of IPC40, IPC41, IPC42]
0x3C0 IPC40 — Interrupt Priority Control Register 40
  [28:26] FDCIP — Interrupt priority
    values as IPC0.INT0IP
  [25:24] FDCIS — Interrupt subpriority
    {v}=Interrupt subpriority is {v} (v=0..3)
  [20:18] MPUPCIP — Interrupt priority
    values as IPC0.INT0IP
  [17:16] MPUPCIS — Interrupt subpriority
    {v}=Interrupt subpriority is {v} (v=0..3)
0x3D0 IPC41 — Interrupt Priority Control Register 41
  [28:26] CRPT1EIP — Interrupt priority
    values as IPC0.INT0IP
  [25:24] CRPT1EIS — Interrupt subpriority
    {v}=Interrupt subpriority is {v} (v=0..3)
  [20:18] CRPT1IP — Interrupt priority
    values as IPC0.INT0IP
  [17:16] CRPT1IS — Interrupt subpriority
    {v}=Interrupt subpriority is {v} (v=0..3)
  [12:10] ETHIP — Interrupt priority
    values as IPC0.INT0IP
  [9:8] ETHIS — Interrupt subpriority
    {v}=Interrupt subpriority is {v} (v=0..3)
  [4:2] CRPTIP — Interrupt priority
    values as IPC0.INT0IP
  [1:0] CRPTIS — Interrupt subpriority
    {v}=Interrupt subpriority is {v} (v=0..3)
0x3E0 IPC42 — Interrupt Priority Control Register 42
  [4:2] CVDIP — Interrupt priority
    values as IPC0.INT0IP
  [1:0] CVDIS — Interrupt subpriority
    {v}=Interrupt subpriority is {v} (v=0..3)
{0x540+4i} OFF{i:03} (i=0..24) — Interrupt Vector Address Offset Register
  [17:1] VOFF — Interrupt Vector {i:03} Address Offset bits
    0=Offset is 0; 1=Offset is 1; 0x10000=Offset is 65536
{0x540+4i} OFF{i:03} (i=30..47) — Interrupt Vector Address Offset Register
  fields as OFF000
{0x540+4i} OFF{i:03} (i=53..64) — Interrupt Vector Address Offset Register
  fields as OFF000
{0x540+4i} OFF{i:03} (i=68..76) — Interrupt Vector Address Offset Register
  fields as OFF000
0x680 OFF080 — Interrupt Vector Address Offset Register
  [17:1] VOFF — Interrupt Vector 080 Address Offset bits
    0=Offset is 0; 1=Offset is 1; 0x10000=Offset is 65536
{0x540+4i} OFF{i:03} (i=83..92) — Interrupt Vector Address Offset Register
  fields as OFF000
{0x540+4i} OFF{i:03} (i=94..97) — Interrupt Vector Address Offset Register
  fields as OFF000
{0x540+4i} OFF{i} (i=100..104) — Interrupt Vector Address Offset Register
  [17:1] VOFF — Interrupt Vector {i} Address Offset bits
    0=Offset is 0; 1=Offset is 1; 0x10000=Offset is 65536
{0x540+4i} OFF{i} (i=106..129) — Interrupt Vector Address Offset Register
  fields as OFF100
{0x540+4i} OFF{i} (i=142..145) — Interrupt Vector Address Offset Register
  fields as OFF100
{0x540+4i} OFF{i} (i=152..157) — Interrupt Vector Address Offset Register
  fields as OFF100
{0x540+4i} OFF{i} (i=162..167) — Interrupt Vector Address Offset Register
  fields as OFF100
